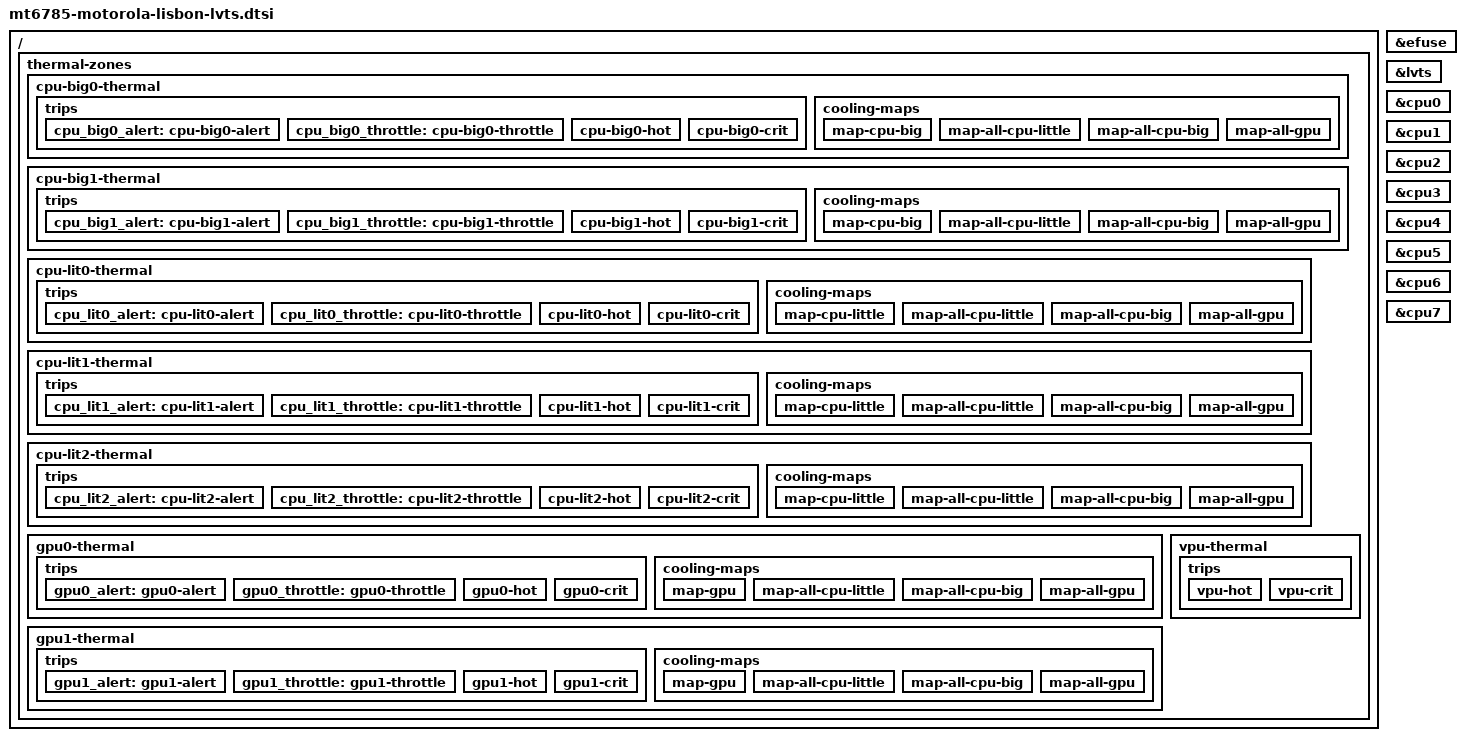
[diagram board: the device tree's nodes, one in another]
// SPDX-License-Identifier: (GPL-2.0 OR MIT)
/*
 * Motorola Moto G60s (lisbon): LVTS die temperature sensors with CPU and GPU cooling.
 *
 * One zone per LVTS sensor: big cluster LVTS1_0/1, LITTLE cluster LVTS2_0/1/2, GPU LVTS3_0/1, VPU
 * LVTS4_0.
 *
 * Trips, all at or below the vendor values: 65 C passive, 85 C passive with every cooling device,
 * 95 C hot (lowest OPP), 110 C critical (orderly shutdown; the vendor resets at 117 C through the
 * LVTS hardware protection, which stays off here). The VPU zone has no cooling device, only hot and
 * critical.
 *
 * Polling only, no trip interrupt: 1 s, 250 ms when passive.
 *
 * #cooling-cells on all CPUs: the CPU maps bind once a cpufreq driver registers the cluster
 * policies (cpu0 = LITTLE cpu0-5, cpu6 = big cpu6-7); without cpufreq they stay unbound and only
 * the GPU is throttled.
 */

#include <dt-bindings/thermal/mediatek,lvts-thermal.h>
#include <dt-bindings/thermal/thermal.h>

&efuse {
	status = "okay";
};

&lvts {
	status = "okay";
};

&cpu0 {
	#cooling-cells = <2>;
};

&cpu1 {
	#cooling-cells = <2>;
};

&cpu2 {
	#cooling-cells = <2>;
};

&cpu3 {
	#cooling-cells = <2>;
};

&cpu4 {
	#cooling-cells = <2>;
};

&cpu5 {
	#cooling-cells = <2>;
};

&cpu6 {
	#cooling-cells = <2>;
};

&cpu7 {
	#cooling-cells = <2>;
};

/ {
	thermal-zones {
		cpu-big0-thermal {
			polling-delay = <1000>;
			polling-delay-passive = <250>;
			thermal-sensors = <&lvts MT6785_BIG_CPU0>;

			trips {
				cpu_big0_alert: cpu-big0-alert {
					temperature = <65000>;
					hysteresis = <2000>;
					type = "passive";
				};

				cpu_big0_throttle: cpu-big0-throttle {
					temperature = <85000>;
					hysteresis = <2000>;
					type = "passive";
				};

				cpu-big0-hot {
					temperature = <95000>;
					hysteresis = <2000>;
					type = "hot";
				};

				cpu-big0-crit {
					temperature = <110000>;
					hysteresis = <0>;
					type = "critical";
				};
			};

			cooling-maps {
				map-cpu-big {
					trip = <&cpu_big0_alert>;
					cooling-device = <&cpu6 THERMAL_NO_LIMIT THERMAL_NO_LIMIT>;
				};

				map-all-cpu-little {
					trip = <&cpu_big0_throttle>;
					cooling-device = <&cpu0 THERMAL_NO_LIMIT THERMAL_NO_LIMIT>;
				};

				map-all-cpu-big {
					trip = <&cpu_big0_throttle>;
					cooling-device = <&cpu6 THERMAL_NO_LIMIT THERMAL_NO_LIMIT>;
				};

				map-all-gpu {
					trip = <&cpu_big0_throttle>;
					cooling-device = <&gpu THERMAL_NO_LIMIT THERMAL_NO_LIMIT>;
				};
			};
		};

		cpu-big1-thermal {
			polling-delay = <1000>;
			polling-delay-passive = <250>;
			thermal-sensors = <&lvts MT6785_BIG_CPU1>;

			trips {
				cpu_big1_alert: cpu-big1-alert {
					temperature = <65000>;
					hysteresis = <2000>;
					type = "passive";
				};

				cpu_big1_throttle: cpu-big1-throttle {
					temperature = <85000>;
					hysteresis = <2000>;
					type = "passive";
				};

				cpu-big1-hot {
					temperature = <95000>;
					hysteresis = <2000>;
					type = "hot";
				};

				cpu-big1-crit {
					temperature = <110000>;
					hysteresis = <0>;
					type = "critical";
				};
			};

			cooling-maps {
				map-cpu-big {
					trip = <&cpu_big1_alert>;
					cooling-device = <&cpu6 THERMAL_NO_LIMIT THERMAL_NO_LIMIT>;
				};

				map-all-cpu-little {
					trip = <&cpu_big1_throttle>;
					cooling-device = <&cpu0 THERMAL_NO_LIMIT THERMAL_NO_LIMIT>;
				};

				map-all-cpu-big {
					trip = <&cpu_big1_throttle>;
					cooling-device = <&cpu6 THERMAL_NO_LIMIT THERMAL_NO_LIMIT>;
				};

				map-all-gpu {
					trip = <&cpu_big1_throttle>;
					cooling-device = <&gpu THERMAL_NO_LIMIT THERMAL_NO_LIMIT>;
				};
			};
		};

		cpu-lit0-thermal {
			polling-delay = <1000>;
			polling-delay-passive = <250>;
			thermal-sensors = <&lvts MT6785_LITTLE_CPU0>;

			trips {
				cpu_lit0_alert: cpu-lit0-alert {
					temperature = <65000>;
					hysteresis = <2000>;
					type = "passive";
				};

				cpu_lit0_throttle: cpu-lit0-throttle {
					temperature = <85000>;
					hysteresis = <2000>;
					type = "passive";
				};

				cpu-lit0-hot {
					temperature = <95000>;
					hysteresis = <2000>;
					type = "hot";
				};

				cpu-lit0-crit {
					temperature = <110000>;
					hysteresis = <0>;
					type = "critical";
				};
			};

			cooling-maps {
				map-cpu-little {
					trip = <&cpu_lit0_alert>;
					cooling-device = <&cpu0 THERMAL_NO_LIMIT THERMAL_NO_LIMIT>;
				};

				map-all-cpu-little {
					trip = <&cpu_lit0_throttle>;
					cooling-device = <&cpu0 THERMAL_NO_LIMIT THERMAL_NO_LIMIT>;
				};

				map-all-cpu-big {
					trip = <&cpu_lit0_throttle>;
					cooling-device = <&cpu6 THERMAL_NO_LIMIT THERMAL_NO_LIMIT>;
				};

				map-all-gpu {
					trip = <&cpu_lit0_throttle>;
					cooling-device = <&gpu THERMAL_NO_LIMIT THERMAL_NO_LIMIT>;
				};
			};
		};

		cpu-lit1-thermal {
			polling-delay = <1000>;
			polling-delay-passive = <250>;
			thermal-sensors = <&lvts MT6785_LITTLE_CPU1>;

			trips {
				cpu_lit1_alert: cpu-lit1-alert {
					temperature = <65000>;
					hysteresis = <2000>;
					type = "passive";
				};

				cpu_lit1_throttle: cpu-lit1-throttle {
					temperature = <85000>;
					hysteresis = <2000>;
					type = "passive";
				};

				cpu-lit1-hot {
					temperature = <95000>;
					hysteresis = <2000>;
					type = "hot";
				};

				cpu-lit1-crit {
					temperature = <110000>;
					hysteresis = <0>;
					type = "critical";
				};
			};

			cooling-maps {
				map-cpu-little {
					trip = <&cpu_lit1_alert>;
					cooling-device = <&cpu0 THERMAL_NO_LIMIT THERMAL_NO_LIMIT>;
				};

				map-all-cpu-little {
					trip = <&cpu_lit1_throttle>;
					cooling-device = <&cpu0 THERMAL_NO_LIMIT THERMAL_NO_LIMIT>;
				};

				map-all-cpu-big {
					trip = <&cpu_lit1_throttle>;
					cooling-device = <&cpu6 THERMAL_NO_LIMIT THERMAL_NO_LIMIT>;
				};

				map-all-gpu {
					trip = <&cpu_lit1_throttle>;
					cooling-device = <&gpu THERMAL_NO_LIMIT THERMAL_NO_LIMIT>;
				};
			};
		};

		cpu-lit2-thermal {
			polling-delay = <1000>;
			polling-delay-passive = <250>;
			thermal-sensors = <&lvts MT6785_LITTLE_CPU2>;

			trips {
				cpu_lit2_alert: cpu-lit2-alert {
					temperature = <65000>;
					hysteresis = <2000>;
					type = "passive";
				};

				cpu_lit2_throttle: cpu-lit2-throttle {
					temperature = <85000>;
					hysteresis = <2000>;
					type = "passive";
				};

				cpu-lit2-hot {
					temperature = <95000>;
					hysteresis = <2000>;
					type = "hot";
				};

				cpu-lit2-crit {
					temperature = <110000>;
					hysteresis = <0>;
					type = "critical";
				};
			};

			cooling-maps {
				map-cpu-little {
					trip = <&cpu_lit2_alert>;
					cooling-device = <&cpu0 THERMAL_NO_LIMIT THERMAL_NO_LIMIT>;
				};

				map-all-cpu-little {
					trip = <&cpu_lit2_throttle>;
					cooling-device = <&cpu0 THERMAL_NO_LIMIT THERMAL_NO_LIMIT>;
				};

				map-all-cpu-big {
					trip = <&cpu_lit2_throttle>;
					cooling-device = <&cpu6 THERMAL_NO_LIMIT THERMAL_NO_LIMIT>;
				};

				map-all-gpu {
					trip = <&cpu_lit2_throttle>;
					cooling-device = <&gpu THERMAL_NO_LIMIT THERMAL_NO_LIMIT>;
				};
			};
		};

		gpu0-thermal {
			polling-delay = <1000>;
			polling-delay-passive = <250>;
			thermal-sensors = <&lvts MT6785_GPU0>;

			trips {
				gpu0_alert: gpu0-alert {
					temperature = <65000>;
					hysteresis = <2000>;
					type = "passive";
				};

				gpu0_throttle: gpu0-throttle {
					temperature = <85000>;
					hysteresis = <2000>;
					type = "passive";
				};

				gpu0-hot {
					temperature = <95000>;
					hysteresis = <2000>;
					type = "hot";
				};

				gpu0-crit {
					temperature = <110000>;
					hysteresis = <0>;
					type = "critical";
				};
			};

			cooling-maps {
				map-gpu {
					trip = <&gpu0_alert>;
					cooling-device = <&gpu THERMAL_NO_LIMIT THERMAL_NO_LIMIT>;
				};

				map-all-cpu-little {
					trip = <&gpu0_throttle>;
					cooling-device = <&cpu0 THERMAL_NO_LIMIT THERMAL_NO_LIMIT>;
				};

				map-all-cpu-big {
					trip = <&gpu0_throttle>;
					cooling-device = <&cpu6 THERMAL_NO_LIMIT THERMAL_NO_LIMIT>;
				};

				map-all-gpu {
					trip = <&gpu0_throttle>;
					cooling-device = <&gpu THERMAL_NO_LIMIT THERMAL_NO_LIMIT>;
				};
			};
		};

		gpu1-thermal {
			polling-delay = <1000>;
			polling-delay-passive = <250>;
			thermal-sensors = <&lvts MT6785_GPU1>;

			trips {
				gpu1_alert: gpu1-alert {
					temperature = <65000>;
					hysteresis = <2000>;
					type = "passive";
				};

				gpu1_throttle: gpu1-throttle {
					temperature = <85000>;
					hysteresis = <2000>;
					type = "passive";
				};

				gpu1-hot {
					temperature = <95000>;
					hysteresis = <2000>;
					type = "hot";
				};

				gpu1-crit {
					temperature = <110000>;
					hysteresis = <0>;
					type = "critical";
				};
			};

			cooling-maps {
				map-gpu {
					trip = <&gpu1_alert>;
					cooling-device = <&gpu THERMAL_NO_LIMIT THERMAL_NO_LIMIT>;
				};

				map-all-cpu-little {
					trip = <&gpu1_throttle>;
					cooling-device = <&cpu0 THERMAL_NO_LIMIT THERMAL_NO_LIMIT>;
				};

				map-all-cpu-big {
					trip = <&gpu1_throttle>;
					cooling-device = <&cpu6 THERMAL_NO_LIMIT THERMAL_NO_LIMIT>;
				};

				map-all-gpu {
					trip = <&gpu1_throttle>;
					cooling-device = <&gpu THERMAL_NO_LIMIT THERMAL_NO_LIMIT>;
				};
			};
		};

		vpu-thermal {
			polling-delay = <1000>;
			polling-delay-passive = <250>;
			thermal-sensors = <&lvts MT6785_VPU>;

			trips {
				vpu-hot {
					temperature = <95000>;
					hysteresis = <2000>;
					type = "hot";
				};

				vpu-crit {
					temperature = <110000>;
					hysteresis = <0>;
					type = "critical";
				};
			};
		};
	};
};
